# tviibh16m register map
Vendor: Infineon Technologies; Series: TVIIBH16M; File version: 1.0
CPU: CM7 r0p1, little endian, MPU, FPU, double-precision FPU, I-cache, D-cache, VTOR, ITCM, DTCM, 3 interrupt priority bits, 16 interrupts
Registers are 32-bit, read-write, reset 0x0 unless marked. A register's access mark holds for its fields unless they carry their own. Offsets are from the block's base; [hi:lo] are bit positions.

## ETH0 (part 1 of 3) — Ethernet Interface
Base 0x40480000
Same registers: ETH1 0x40490000
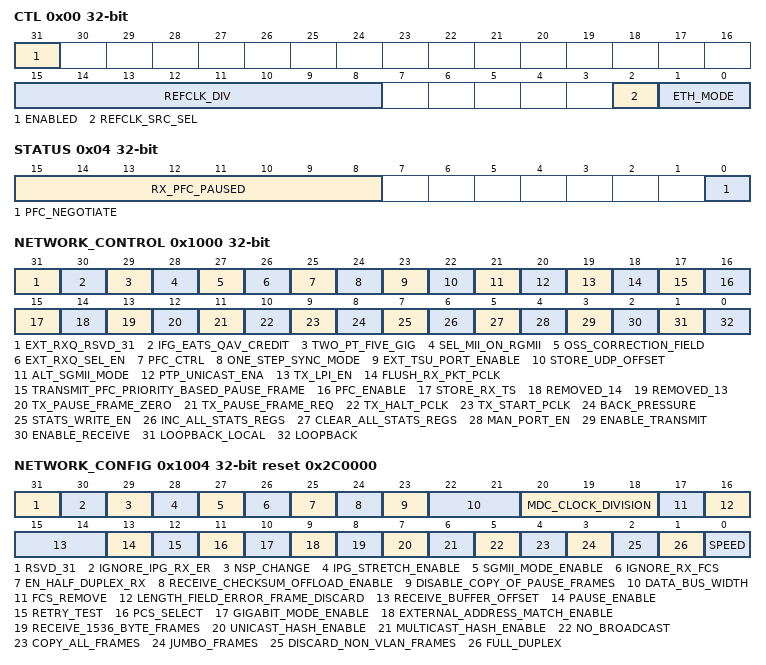
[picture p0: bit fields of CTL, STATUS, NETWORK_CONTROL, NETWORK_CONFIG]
0x00 CTL — MXETH Control Register
  [31] ENABLED — MXETH enable: '0': Disabled. '1': Enabled.
  [15:8] REFCLK_DIV — Specify the ref_clk divider. Integer division by (1+REFCLK_DIV). Allows for integer divisions in the range [1, 256].
  [2] REFCLK_SRC_SEL — Select the source for ref_clk. 0: Ref_clk comes from REF_CLK_IN input port (HSIO). 1: Ref_clk comes from REF_CLK_INT_IN input port (PLL).
  [1:0] ETH_MODE — Set ethernet mode. The speed of 10M/100M/1G is selected by programming network_config after IP is enabled. The field also specifies the clock source of internal tx_clk and rx_clk domain.
    0=MII (MII mode (10/100MHz speed is determined by network_config[0]).); 1=GMII (GMII mode (network_config[10] must be set to enable 1G operation).); 2=RGMII (RGMII mode (10M/100M/1G speed is determined by network_config[10] and network_config[0]).); 3=RMII (RMII mode (10M/100M speed is determined by network_config[0]).)
0x04 STATUS ro — MXETH Status Register
  [15:8] RX_PFC_PAUSED — Each bit corresponds to a priority indicated within the PFC priority based pause frame. Each bit is set when a PFC priority based pause frame has been received, and the associated priority pause time quantum is non-zero. Each bit is cleared when the associated pause time identified by the received pause time quantum has elapsed.
  [0] PFC_NEGOTIATE — Identifies that PFC priority based pause flow control has been negotiated. 0 - No PFC priority based pause frames have yet been received, flow control is being handled using classic 802.3 pause frames. 1 - At least one PFC priority based pause frames has been received. All subsequent 802.3 pause frames will be dropped.
0x1000 NETWORK_CONTROL — The network control register contains general MAC control functions for both receiver and transmitter.
  [31] EXT_RXQ_RSVD_31 ro
  [30] IFG_EATS_QAV_CREDIT — Setting this bit high modifies the CBS algorithm so the IFG/IPG associated with a transmit frame counts towards its 802.1Qav credit.
  [29] TWO_PT_FIVE_GIG — 2.5G operation selected - setting this bit high drives the speed_mode[3] top level output pin high and also adjusts the link timer in the PCS auto-negotiation block to ensure it delivers 10ms for 2500BASE-X and 1.6ms in SGMII mode, and also ensures int_moderation counts 800ns periods with the speeded up MAC clocks.
  [28] SEL_MII_ON_RGMII — If the RGMII interface being used set this bit high to configure the interface for MII operation.
  [27] OSS_CORRECTION_FIELD — 1588 One Step Correction Field Update. Set this bit high to enable updating the correction field of PTP 1588 version 2 sync frames by adding current TSU timer value.
  [26] EXT_RXQ_SEL_EN — Enable external selection of receive queue. When this bit is high the ext_match1, ext_match2, ext_match3 and ext_match4 inputs will determine which receive queue a frame is routed to. This will be the case regardless of the state of the external address match enable bit 9 of the network config register. Note that receive frames will be dropped unless they are matched by the internal frame filtering functionality. If the external address match enable bit 9 in the network config register is set frames may be matched by an external address match filter as long as one of the ext_match1, ext_match2, ext_match3 and ext_match4 inputs is asserted early enough. When set ext_rxq_sel_en takes precedence over the existing screener functionality. This bit is only relevant if priority queuing is configured.
  [25] PFC_CTRL — 'Enable multiple PFC pause quantums, one per pause priority'
  [24] ONE_STEP_SYNC_MODE — 1588 One Step Sync Mode. Write 1 to enable. Replace timestamp field in the 1588 header for TX Sync Frames with current TSU timer value.
  [23] EXT_TSU_PORT_ENABLE ro — Write ignore, read 0
  [22] STORE_UDP_OFFSET
  [21] ALT_SGMII_MODE — Alternative sgmii mode. If asserted with sgmii_mode in the network control register the ACK bit is driven before ability detect during transfer of status information from the PHY to the MAC.
  [20] PTP_UNICAST_ENA — Enable detection of unicast PTP unicast frames.
  [19] TX_LPI_EN — Enable LPI transmission when set LPI (low power idle) is immediately transmitted. LPI is transmitted even if bit 3 transmit enable is disabled. Setting this bit also sends a pause signal to the transmit datapath.
  [18] FLUSH_RX_PKT_PCLK wo — Flush the next packet from the external RX DPRAM. Writing one to this bit will only have an effect if the DMA is not currently writing a packet already stored in the DPRAM to memory. Self clearing register.
  [17] TRANSMIT_PFC_PRIORITY_BASED_PAUSE_FRAME wo — Write a one to transmit PFC priority based pause frame. Takes the values stored in the Transmit PFC Pause Register. Self clearing register.
  [16] PFC_ENABLE — Enable PFC Priority Based Pause Reception capabilities. Setting this bit will enable PFC negotiation and recognition of priority based pause frames.
  [15] STORE_RX_TS — Store receive time stamp to memory. Setting this bit to one will cause the CRC of every received frame to be replaced with the value of the nanoseconds field of the 1588 timer that was captured as the receive frame passed the message time stamp point. Set to zero for normal operation.
  [14] REMOVED_14 ro — Write ignore, read 0
  [13] REMOVED_13 ro — Write ignore, read 0
  [12] TX_PAUSE_FRAME_ZERO wo — Transmit zero quantum pause frame - writing one to this bit causes a pause frame with zero quantum to be transmitted.
  [11] TX_PAUSE_FRAME_REQ wo — Transmit pause frame - writing one to this bit causes a pause frame to be transmitted. Self clearing register.
  [10] TX_HALT_PCLK wo — Transmit halt - writing one to this bit halts transmission as soon as any ongoing frame transmission ends.
  [9] TX_START_PCLK wo — Start transmission - writing one to this bit starts transmission.
  [8] BACK_PRESSURE — Back pressure if set in 10M or 100M half duplex mode will force collisions on all received frames. Ignored in gigabit half duplex mode.
  [7] STATS_WRITE_EN — Write enable for statistics registers - setting this bit to one means the statistics registers can be written for functional test purposes.
  [6] INC_ALL_STATS_REGS wo — Incremental statistics registers - this bit is write only. Writing a one increments all the statistics registers by one for test purposes. Self clearing register.
  [5] CLEAR_ALL_STATS_REGS wo — Clear statistics registers - this bit is write only. Writing a one clears the statistics registers. Self clearing register.
  [4] MAN_PORT_EN — Management port enable - set to one to enable the management port. When zero forces mdio to high impedance state and mdc low.
  [3] ENABLE_TRANSMIT — Transmit enable - when set, it enables the GEM transmitter to send data. When reset transmission will stop immediately, the transmit pipeline and control registers will be cleared and the transmit queue pointer register will reset to point to the start of the transmit descriptor list.
  [2] ENABLE_RECEIVE — Receive enable - when set, it enables the GEM to receive data. When reset frame reception will stop immediately and the receive pipeline will be cleared. The receive queue pointer register is unaffected.
  [1] LOOPBACK_LOCAL — Loopback local - asserts the loopback_local signal to the system clock generator. Also connects txd to rxd, tx_en to rx_dv and forces full duplex mode. Bit 11 of the network configuration register must be set low to disable TBI mode when in internal loopback. rx_clk and tx_clk may malfunction as the GEM is switched into and out of internal loopback. It is important that receive and transmit circuits have already been disabled when making the switch into and out of internal loopback. Local loopback functionality is optional and may not be supported by some instantiations of the GEM.
  [0] LOOPBACK — Loopback - controls the loopback output pin.
0x1004 NETWORK_CONFIG reset 0x2C0000 — The network configuration register contains functions for setting the mode of operation for the Gigabit Ethernet MAC.
  [31] RSVD_31
  [30] IGNORE_IPG_RX_ER — Ignore IPG rx_er. When set rx_er has no effect on the GEMs operation when rx_dv is low. Set this when using the RGMII wrapper in half-duplex mode.
  [29] NSP_CHANGE — Receive bad preamble. When set frames with non-standard preamble are not rejected.
  [28] IPG_STRETCH_ENABLE — IPG stretch enable - when set the transmit IPG can be increased above 96 bit times depending on the previous frame length using the IPG stretch register.
  [27] SGMII_MODE_ENABLE — SGMII mode enable - changes behaviour of the auto-negotiation advertisement and link partner ability registers to meet the requirements of SGMII and reduces the duration of the link timer from 10 ms to 1.6 ms.
  [26] IGNORE_RX_FCS — Ignore RX FCS - when set frames with FCS/CRC errors will not be rejected. FCS error statistics will still be collected for frames with bad FCS and FCS status will be recorded in frame's DMA descriptor. For normal operation this bit must be set to zero.
  [25] EN_HALF_DUPLEX_RX — Enable frames to be received in half-duplex mode while transmitting. Must set '0', MXETH only supports full-duplex mode.
  [24] RECEIVE_CHECKSUM_OFFLOAD_ENABLE — Receive checksum offload enable - when set, the receive checksum engine is enabled. Frames with bad IP, TCP or UDP checksums are discarded.
  [23] DISABLE_COPY_OF_PAUSE_FRAMES — Disable copy of pause frames - set to one to prevent pause frames being copied to memory. When set, neither control frames with type id 8808, nor pause frames with destination address 010000c28001 are copied to memory, this functionality was enhanced in release 1p09 (mxeth uses 1p09). Note that valid pause frames received will still increment pause statistics and pause the transmission of frames as required.
  [22:21] DATA_BUS_WIDTH — Data bus width - set according to AMBA (AXI/AHB) or external FIFO data bus width. The reset value for this can be changed by defining a new value for gem_dma_bus_width_def in gem_defs. Only valid bus widths may be written if the system is configured to a maximum width less than 128-bits. 00: 32 bit data bus width 01: 64 bit AMBA (AXI/AHB) data bus width 10: 128 bit AMBA (AXI/AHB) data bus width 11: 128 bit AMBA (AXI/AHB) data bus width. Note. The reset value of this field is equal to the gem_dma_bus_width_def define, which is user configurable. Note: For AXI_MASTER_PRESENT=1, MXETH only supports 64b DMA data bus width, so must set it 1. For AXI_MASTER_PRESENT=0, MXETH only supports 32b DMA data bus width, so must set it 0.
  [20:18] MDC_CLOCK_DIVISION — MDC clock division - set according to pclk speed. These three bits determine the number pclk will be divided by to generate MDC. For conformance with the 802.3 specification, MDC must not exceed 2.5 MHz (MDC is only active during MDIO read and write operations). The reset value for this can be changed by defining a new value for gem_mdc_clock_div in gem_defs.v 000: divide pclk by 8 (pclk up to 20 MHz) 001: divide pclk by 16 (pclk up to 40 MHz) 010: divide pclk by 32 (pclk up to 80 MHz) 011: divide pclk by 48 (pclk up to 120MHz) 100: divide pclk by 64 (pclk up to 160 MHz) 101: divide pclk by 96 (pclk up to 240 MHz) 110: divide pclk by 128 (pclk up to 320 MHz) 111: divide pclk by 224 (pclk up to 540 MHz). Note. The reset value of this field is equal to the gem_mdc_clock_div define, which is user configurable.
  [17] FCS_REMOVE — FCS remove - setting this bit will cause received frames to be written to memory without their frame check sequence (last 4 bytes). The frame length indicated will be reduced by four bytes in this mode.
  [16] LENGTH_FIELD_ERROR_FRAME_DISCARD — Length field error frame discard - setting this bit causes frames with a measured length shorter than the extracted length field (as indicated by bytes 13 and 14 in a non-VLAN tagged frame) to be discarded. This only applies to frames with a length field less than 0x0600.
  [15:14] RECEIVE_BUFFER_OFFSET — Receive buffer offset - indicates the number of bytes by which the received data is offset from the start of the receive buffer.
  [13] PAUSE_ENABLE — Pause enable - when set, transmission will pause if a non zero 802.3 classic pause frame is received and PFC has not been negotiated.
  [12] RETRY_TEST — Retry test - must be set to zero for normal operation. If set to one the backoff between collisions will always be one slot time. Setting this bit to one helps test the too many retries condition. Also used in the pause frame tests to reduce the pause counter's decrement time from 512 bit times, to every rx_clk cycle.
  [11] PCS_SELECT — PCS select - selects between MII/GMII and TBI
  [10] GIGABIT_MODE_ENABLE — Gigabit mode enable - setting this bit configures the GEM for 1000 Mbps operation. 0: 10/100 operation using MII interface 1: Gigabit operation using GMI interface
  [9] EXTERNAL_ADDRESS_MATCH_ENABLE — External address match enable - when set the external address match interface can be used to copy frames to memory.
  [8] RECEIVE_1536_BYTE_FRAMES — Receive 1536 byte frames - setting this bit means the GEM will accept frames up to 1536 bytes in length. Normally the GEM would reject any frame above 1518 bytes.
  [7] UNICAST_HASH_ENABLE — Unicast hash enable - when set, unicast frames will be accepted when the 6 bit hash function of the destination address points to a bit that is set in the hash register.
  [6] MULTICAST_HASH_ENABLE — Multicast hash enable - when set, multicast frames will be accepted when the 6 bit hash function of the destination address points to a bit that is set in the hash register.
  [5] NO_BROADCAST — No broadcast - when set to logic one, frames addressed to the broadcast address of all ones will not be accepted.
  [4] COPY_ALL_FRAMES — Copy all frames - when set to logic one, all valid frames will be accepted.
  [3] JUMBO_FRAMES — Jumbo frames - set to one to enable jumbo frames up to `gem_jumbo_max_length bytes to be accepted. The default length is 10,240 bytes.
  [2] DISCARD_NON_VLAN_FRAMES — Discard non-VLAN frames - when set only VLAN tagged frames will be passed to the address matching logic.
  [1] FULL_DUPLEX — Full duplex - if set to logic one, the transmit block ignores the state of collision and carrier sense and allows receive while transmitting. Also controls the half_duplex pin.
  [0] SPEED — Speed - set to logic one to indicate 100Mbps operation, logic zero for 10Mbps.
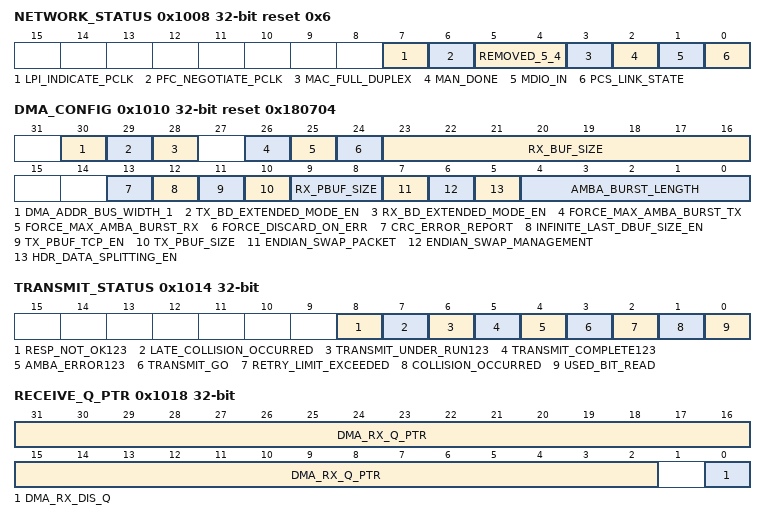
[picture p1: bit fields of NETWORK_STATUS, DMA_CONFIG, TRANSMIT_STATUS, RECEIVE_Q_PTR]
0x1008 NETWORK_STATUS ro reset 0x6 — The network status register returns status information with respect to the PHY management interface.
  [7] LPI_INDICATE_PCLK — LPI Indication - Low power idle has been detected on receive. This bit is set when LPI is detected and reset when normal idle is detected. An interrupt is generated when the state of this bit changes.
  [6] PFC_NEGOTIATE_PCLK — Set when PFC Priority Based Pause has been negotiated.
  [5:4] REMOVED_5_4
  [3] MAC_FULL_DUPLEX — PCS auto-negotiation duplex resolution. Set to one if the resolution function determines that both devices are capable of full duplex operation. If zero half-duplex operation is possible as long as bit 0 (PCS link state) is also one.
  [2] MAN_DONE — The PHY management logic is idle (i.e. has completed).
  [1] MDIO_IN — Returns status of the mdio_in pin.
  [0] PCS_LINK_STATE — Returns status of PCS link state. If auto-negotiation is disabled this returns the synchronisation status. If auto-negotiation is enabled it is set in the LINK_OK state as long as a compatible duplex mode is resolved.
0x100C USER_IO_REGISTER ro — Not presents. Access to the register will return AHB error.
  [31:0] RSVD_31_0 — Write ignore, read 0
0x1010 DMA_CONFIG reset 0x180704 — DMA Configuration Register
  [30] DMA_ADDR_BUS_WIDTH_1 — DMA address bus width. 0 = 32b, 1 = 64b. MXETH only supports 32b DMA address bus width, so must set it 0.
  [29] TX_BD_EXTENDED_MODE_EN — Enable TX extended BD mode. See TX BD control register definition for description of feature.
  [28] RX_BD_EXTENDED_MODE_EN — Enable RX extended BD mode. See RX BD control register definition for description of feature.
  [26] FORCE_MAX_AMBA_BURST_TX — Force max length bursts on TX. Force the TX DMA to always issue max length bursts on EOP(end of packet) or EOB(end of buffer) transfers as defined by bits 4:0 of this register, even when there is less that max burst data bytes to read. Residual data read is ignored. Does not apply on bursts that break 1k boundary rule.
  [25] FORCE_MAX_AMBA_BURST_RX — Force max length bursts on RX. Force the RX DMA to always issue max length bursts on EOP(end of packet) or EOB(end of buffer)transfers, even if there is less than max burst real packet data required to write. Any extra bytes of pad data is set to 0x00. Does not apply on bursts that break 1k boundary rule.
  [24] FORCE_DISCARD_ON_ERR — Auto Discard RX pkts during lack of resource. When set, the GEM DMA will automatically discard receive packets from the receiver packet buffer memory when no AMBA (AXI/AHB) resource is available. When low, then received packets will remain to be stored in the SRAM based packet buffer until AMBA (AXI/AHB) buffer resource next becomes available. A write to this bit is ignored if the DMA is not configured in the packet buffer full store and forward mode.
  [23:16] RX_BUF_SIZE — DMA receive buffer size in external AMBA (AXI/AHB) system memory. The value defined by these bits determines the size of buffer to use in main system memory when writing received data. The value is defined in multiples of 64 bytes. 0x01 corresponds to buffers of 64 bytes 0x02 corresponds to 128 bytes etc. For example: 0x02: 128 byte. 0x18: 1536 byte (1*max length frame/buffer) 0xA0: 10240 byte (1*10K jumbo frame/buffer) Note that this value should never be written as zero. Note. The reset value of this field is equal to the gem_rx_buffer_length_def define, which is user configurable.
  [13] CRC_ERROR_REPORT — When the bit is set, bit 16 of the receive buffer descriptor will represent FCS/CRC error (only if frames with FCS are copied to memory as enabled by bit 26 in the network config register). When this bit is clear, bit 16 of the receive buffer descriptor will represent the Canonical format indicator (CFI) bit as extracted from the receive frame (if the receive buffer descriptor is pointing to the last data buffer of the receive frame and the received frame was VLAN tagged).
  [12] INFINITE_LAST_DBUF_SIZE_EN — Forces the DMA to consider the data buffer pointed to by last descriptor in the descriptor list to be of infinite size.
  [11] TX_PBUF_TCP_EN
  [10] TX_PBUF_SIZE
  [9:8] RX_PBUF_SIZE
  [7] ENDIAN_SWAP_PACKET — endian swap mode enable for packet data accesses. When set, selects swapped endianism for AMBA (AXI/AHB) transfers. When clear, selects little endian mode. Note, the default value of this bit equals to `gem_endian_swap_def, which is design time configuration.
  [6] ENDIAN_SWAP_MANAGEMENT — endian swap mode enable for management descriptor accesses. When set, selects swapped endianism for AMBA (AXI/AHB) transfers. When clear, selects little endian mode. Note, the default value of this bit equals to `gem_endian_swap_def, which is design time configuration.
  [5] HDR_DATA_SPLITTING_EN — Enable header data Splitting. When set, receive frames will be forwarded to main memory using a minimum of two DMA data buffers. The first X data buffers will contain the frame header, consisting of the Ethernet,VLAN,(IPv4 or IPv6),(TCP or UDP). X= (frame header size divided by rx_buf_size as defined in bits 23:16 of this register). The last Y data buffers will contain the frame payload. Y= (frame payload size divided by rx_buf_size). Note that for non VLAN/IP/TCP/UDP frames, the header will always be 14 bytes. When this feature is disabled, the frame is forwarded to main memory in blocks of rx_buf_size. Note: For AXI_MASTER_PRESENT=0 i.e. AHB master support, this feature cannot be set.
  [4:0] AMBA_BURST_LENGTH — Selects the burst length to use on the AMBA (AHB/AXI) when transferring frame data. Not used for DMA management operations and only used where space and data size allow and respecting AXI/AHB burst boundary rules. One-hot priority encoding enforced automatically on register writes as follows, where x represents don't care: 1xxxx: Attempt to use bursts of up to 16. 01xxx: Attempt to use bursts of up to 8. 001xx: Attempt to use bursts of up to 4. 0001x: Always use SINGLE bursts. 00001: Always use SINGLE bursts. 00000: Attempt to use bursts of up to 256. Note: MXETH only supports burst length up to 16.
0x1014 TRANSMIT_STATUS — This register, when read, provides details of the status of a transmit. Once read, individual bits may be cleared by writing 1 to them. It is not possible to set a bit to 1 by writing to the register.
  [8] RESP_NOT_OK123 write-1-clears — bresp/hresp not OK - set when the DMA block sees bresp/hresp not OK. Cleared by writing a one to this bit.
  [7] LATE_COLLISION_OCCURRED write-1-clears — Late collision occurred - only set if the condition occurs in gigabit mode, as retry is not attempted. Cleared by writing a one to this bit.
  [6] TRANSMIT_UNDER_RUN123 write-1-clears — Transmit under run - this bit is set if the transmitter was forced to terminate a frame that it had already began transmitting due to further data being unavailable. This bit is set if a transmitter status write back has not completed when another status write back is attempted. When using the DMA interface configured for packet buffer mode, this bit will never be set. Cleared by writing a 1.
  [5] TRANSMIT_COMPLETE123 write-1-clears — Transmit complete - set when a frame has been transmitted. Cleared by writing a one to this bit.
  [4] AMBA_ERROR123 write-1-clears — Transmit frame corruption due to AMBA (AXI/AHB) errors. Set if an error occurs whilst midway through reading transmit frame from external memory including RRESP or BRESP errors and buffers exhausted mid frame (if the buffers run out during transmission of a frame then transmission stops, FCS shall be bad and tx_er asserted). Also set in DMA packet buffer mode if single frame is too large for configured packet buffer memory size. Cleared by writing a one to this bit.
  [3] TRANSMIT_GO ro — Transmit go - if high transmit is active. When using the exposed FIFO interface, this bit represents bit 3 of the network control register. When using the DMA interface this bit represents the tx_go variable as specified in the transmit buffer description.
  [2] RETRY_LIMIT_EXCEEDED write-1-clears — Retry limit exceeded - cleared by writing a one to this bit.
  [1] COLLISION_OCCURRED write-1-clears — Collision occurred - set by the assertion of collision. Cleared by writing a one to this bit. When operating in 10/100 mode, this status indicates either a collision or a late collision. In gigabit mode, this status is not set for a late collision.
  [0] USED_BIT_READ write-1-clears — Used bit read - set when a transmit buffer descriptor is read with its used bit set. Cleared by writing a one to this bit.
0x1018 RECEIVE_Q_PTR — This register holds the start address of the receive buffer queue (receive buffers descriptor list). The receive buffer queue base address must be initialized before receive is enabled through bit 2 of the network control register. Once reception is enabled, any write to the receive buffer queue base address register is ignored. Reading this register returns the location of the descriptor currently being accessed. This value increments as buffers are used. Software should not use this register for determining where to remove received frames from the queue as it constantly changes as new frames are received. Software should instead work its way through the buffer descriptor queue checking the used bits. In terms of AMBA (AXI) operation, the receive descriptors are read from memory using a single 32bit AXI access. When the datapath is configured at 64bit, the receive descriptors should be aligned at 64-bit boundaries and each pair of 32-bit descriptors is written to using a single 64bit AXI access.
  [31:2] DMA_RX_Q_PTR — Receive buffer queue base address - written with the address of the start of the receive queue.
  [0] DMA_RX_DIS_Q — Disable queue if set to 1. This can be used to reduce the number of active queues and should only be changed while receive is not enabled.
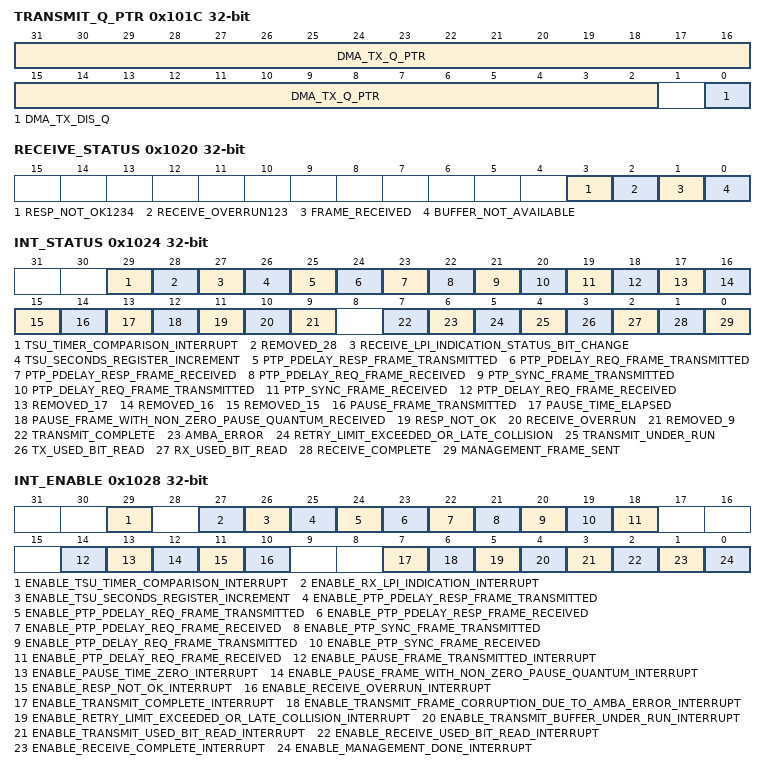
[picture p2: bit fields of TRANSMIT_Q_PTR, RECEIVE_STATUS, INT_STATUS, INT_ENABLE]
0x101C TRANSMIT_Q_PTR — This register holds the start address of the transmit buffer queue (transmit buffers descriptor list). The transmit buffer queue base address register must be initialized before transmit is started through bit 9 of the network control register. Once transmission has started, any write to the transmit buffer queue base address register is illegal and therefore ignored. Note that due to clock boundary synchronization, it takes a maximum of four pclk cycles from the writing of the transmit start bit before the transmitter is active. Writing to the transmit buffer queue base address register during this time may produce unpredictable results. Reading this register returns the location of the descriptor currently being accessed. Because the DMA can store data for multiple frames at once, this may not necessarily be pointing to the current frame being transmitted. In terms of AMBA AXI operation, the transmit descriptors are written to memory using a single 32bit AHB access. When the datapath is configured as 64bit, the transmit descriptors should be aligned at 64-bit boundaries and each pair of 32-bit descriptors is read from memory using a single AXI access.
  [31:2] DMA_TX_Q_PTR — Transmit buffer queue base address - written with the address of the start of the transmit queue.
  [0] DMA_TX_DIS_Q — Disable queue if set to 1. This can be used to reduce the number of active queues and should only be changed while transmit is not enabled.
0x1020 RECEIVE_STATUS — This register, when read provides details of the status of a receive. Once read, individual bits may be cleared by writing 1 to them. It is not possible to set a bit to 1 by writing to the register.
  [3] RESP_NOT_OK1234 write-1-clears — bresp not OK - set when the DMA block sees bresp/hresp not OK. Cleared by writing a one to this bit.
  [2] RECEIVE_OVERRUN123 write-1-clears — Receive overrun - this bit is set if either the gem_dma RX FIFO or external RX FIFO were unable to store the receive frame due to a FIFO overflow, or if the receive status, reported by the gem_rx module to the gem_dma was not taken at end of frame. This bit is also set in DMA packet buffer mode if the packet buffer overflows. For DMA operation the buffer will be recovered if an overrun occurs. This bit is cleared by writing a one to it.
  [1] FRAME_RECEIVED write-1-clears — Frame received - one or more frames have been received and placed in memory. Cleared by writing a one to this bit.
  [0] BUFFER_NOT_AVAILABLE write-1-clears — Buffer not available - an attempt was made to get a new buffer and the pointer indicated that it was owned by the processor. The DMA will reread the pointer each time an end of frame is received until a valid pointer is found. This bit is set following each descriptor read attempt that fails, even if consecutive pointers are unsuccessful and software has in the mean time cleared the status flag. Cleared by writing a one to this bit.
0x1024 INT_STATUS — If not configured for priority queueing, the GEM generates a single interrupt. This register indicates the source of this interrupt. The corresponding bit in the mask register must be clear for a bit to be set. If any bit is set in this register the ethernet_int signal will be asserted. For test purposes each bit can be set or reset by writing to the interrupt mask register. The default configuration is shown below whereby all bits are reset to zero on read. Changing the validity of the `gem_irq_read_clear define will instead require a one to be written to the appropriate bit in order to clear it. In this mode reading has no affect on the status of the bit.
  [29] TSU_TIMER_COMPARISON_INTERRUPT wo write-1-clears — TSU timer comparison interrupt. Indicates when TSU timer count value is equal to programmed value.
  [28] REMOVED_28 ro — Write ignore, read 0
  [27] RECEIVE_LPI_INDICATION_STATUS_BIT_CHANGE wo write-1-clears
  [26] TSU_SECONDS_REGISTER_INCREMENT wo write-1-clears — TSU seconds register increment indicates the register has incremented. Cleared on read.
  [25] PTP_PDELAY_RESP_FRAME_TRANSMITTED wo write-1-clears — PTP pdelay_resp frame transmitted indicates a PTP pdelay_resp frame has been transmitted. Cleared on read.
  [24] PTP_PDELAY_REQ_FRAME_TRANSMITTED wo write-1-clears — PTP pdelay_req frame transmitted indicates a PTP pdelay_req frame has been transmitted. Cleared on read.
  [23] PTP_PDELAY_RESP_FRAME_RECEIVED wo write-1-clears — PTP pdelay_resp frame received indicates a PTP pdelay_resp frame has been received. Cleared on read.
  [22] PTP_PDELAY_REQ_FRAME_RECEIVED wo write-1-clears — PTP pdelay_req frame received indicates a PTP pdelay_req frame has been received. Cleared on read.
  [21] PTP_SYNC_FRAME_TRANSMITTED wo write-1-clears — PTP sync frame transmitted indicates a PTP sync frame has been transmitted. Cleared on read.
  [20] PTP_DELAY_REQ_FRAME_TRANSMITTED wo write-1-clears — PTP delay_req frame transmitted indicates a PTP delay_req frame has been transmitted. Cleared on read.
  [19] PTP_SYNC_FRAME_RECEIVED wo write-1-clears — PTP sync frame received indicates a PTP sync frame has been received. Cleared on read.
  [18] PTP_DELAY_REQ_FRAME_RECEIVED wo write-1-clears — PTP delay_req frame received indicates a PTP delay_req frame has been received. Cleared on read.
  [17] REMOVED_17 ro — Write ignore, read 0
  [16] REMOVED_16 ro — Write ignore, read 0
  [15] REMOVED_15 ro — Write ignore, read 0
  [14] PAUSE_FRAME_TRANSMITTED wo write-1-clears — Pause frame transmitted - indicates a pause frame has been successfully transmitted after being initiated from the network control register or from the tx_pause control pin. Cleared on read.
  [13] PAUSE_TIME_ELAPSED wo write-1-clears — Pause Time elapsed. set when either the pause time register at address 0x38 decrements to zero, or when a valid pause frame is received with a zero pause quantum field. Cleared on read.
  [12] PAUSE_FRAME_WITH_NON_ZERO_PAUSE_QUANTUM_RECEIVED wo write-1-clears — Pause frame with non-zero pause quantum received - indicates a valid pause has been received that has a non-zero pause quantum field. Cleared on read.
  [11] RESP_NOT_OK wo write-1-clears — bresp not OK - set when the DMA block sees bresp not OK. Cleared on read.
  [10] RECEIVE_OVERRUN wo write-1-clears — Receive overrun - set when the receive overrun status bit gets set. Cleared on read.
  [9] REMOVED_9 ro — Write ignore, read 0
  [7] TRANSMIT_COMPLETE wo write-1-clears — Transmit complete - set when a frame has been transmitted. Cleared on read.
  [6] AMBA_ERROR write-1-clears — Transmit frame corruption due to AMBA (AXI/AHB) error. Set if an error occurs whilst midway through reading transmit frame from external system memory, including HRESP (AHB), RRESP or BRESP(AXI) errors and buffers exhausted mid frame (if the buffers run out during transmission of a frame then transmission stops, FCS shall be bad and tx_er asserted). Also set in DMA packet buffer mode if single frame is too large for configured packet buffer memory size. Cleared on a read.
  [5] RETRY_LIMIT_EXCEEDED_OR_LATE_COLLISION write-1-clears — Retry limit exceeded or late collision - transmit error. Late collision will only cause this status bit to be set in gigabit mode (as a retry is not attempted). Cleared on read.
  [4] TRANSMIT_UNDER_RUN write-1-clears — Transmit under run - this interrupt is set if the transmitter was forced to terminate a frame that it has already began transmitting due to further data being unavailable. If an under run occurs, the transmitter will force bad crc and tx_er high. This interrupt is set if a transmitter status write back has not completed when another status write back is attempted. When using the DMA interface configured for internal FIFO mode, this interrupt is also set when the transmit DMA has written the SOP data into the FIFO and either the AHB bus was not granted in time for further data, or because an AHB/AXI error response was returned by the connected slave, or because a used bit was read. When using the DMA interface configured for packet buffer mode, this bit will never be set. When using the external FIFO interface, this interrupt is also set when the tx_r_underflow input was asserted during a frame transfer. Cleared on read.
  [3] TX_USED_BIT_READ write-1-clears — TX used bit read - set when a transmit buffer descriptor is read with its used bit set. Cleared on read.
  [2] RX_USED_BIT_READ write-1-clears — RX used bit read - set when a receive buffer descriptor is read with its used bit set. Cleared on read.
  [1] RECEIVE_COMPLETE write-1-clears — Receive complete - a frame has been stored in memory. Cleared on read.
  [0] MANAGEMENT_FRAME_SENT write-1-clears — Management frame sent - the PHY maintenance register has completed its operation. Cleared on read.
0x1028 INT_ENABLE wo — At reset all interrupts are disabled. Writing a one to the relevant bit location enables the required interrupt. This register is write only and when read will return zero.
  [29] ENABLE_TSU_TIMER_COMPARISON_INTERRUPT
  [27] ENABLE_RX_LPI_INDICATION_INTERRUPT
  [26] ENABLE_TSU_SECONDS_REGISTER_INCREMENT
  [25] ENABLE_PTP_PDELAY_RESP_FRAME_TRANSMITTED
  [24] ENABLE_PTP_PDELAY_REQ_FRAME_TRANSMITTED
  [23] ENABLE_PTP_PDELAY_RESP_FRAME_RECEIVED
  [22] ENABLE_PTP_PDELAY_REQ_FRAME_RECEIVED
  [21] ENABLE_PTP_SYNC_FRAME_TRANSMITTED
  [20] ENABLE_PTP_DELAY_REQ_FRAME_TRANSMITTED
  [19] ENABLE_PTP_SYNC_FRAME_RECEIVED
  [18] ENABLE_PTP_DELAY_REQ_FRAME_RECEIVED
  [14] ENABLE_PAUSE_FRAME_TRANSMITTED_INTERRUPT
  [13] ENABLE_PAUSE_TIME_ZERO_INTERRUPT
  [12] ENABLE_PAUSE_FRAME_WITH_NON_ZERO_PAUSE_QUANTUM_INTERRUPT
  [11] ENABLE_RESP_NOT_OK_INTERRUPT — Enable bresp not OK interrupt
  [10] ENABLE_RECEIVE_OVERRUN_INTERRUPT
  [7] ENABLE_TRANSMIT_COMPLETE_INTERRUPT
  [6] ENABLE_TRANSMIT_FRAME_CORRUPTION_DUE_TO_AMBA_ERROR_INTERRUPT — Enable transmit frame corruption due to AMBA (AXI/AHB) error interrupt
  [5] ENABLE_RETRY_LIMIT_EXCEEDED_OR_LATE_COLLISION_INTERRUPT
  [4] ENABLE_TRANSMIT_BUFFER_UNDER_RUN_INTERRUPT
  [3] ENABLE_TRANSMIT_USED_BIT_READ_INTERRUPT
  [2] ENABLE_RECEIVE_USED_BIT_READ_INTERRUPT
  [1] ENABLE_RECEIVE_COMPLETE_INTERRUPT
  [0] ENABLE_MANAGEMENT_DONE_INTERRUPT
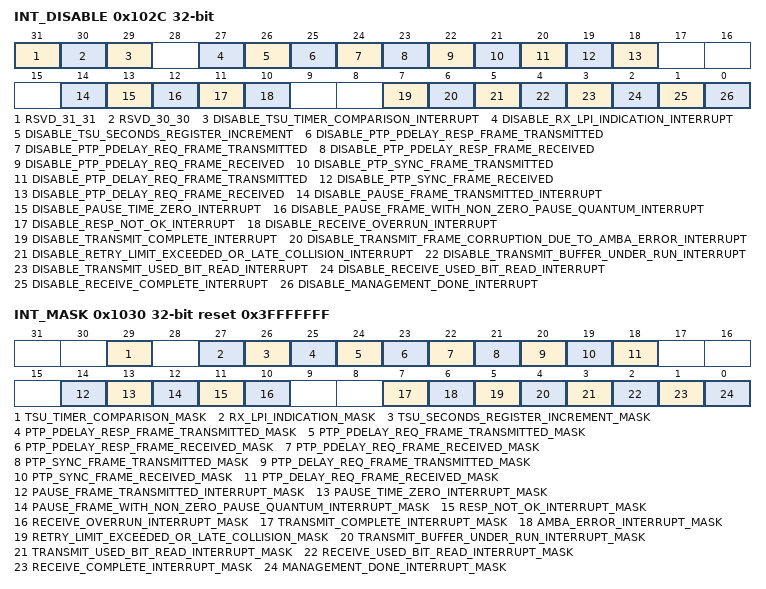
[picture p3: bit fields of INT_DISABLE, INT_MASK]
0x102C INT_DISABLE — Writing a 1 to the relevant bit location disables that particular interrupt. This register is write only and when read will return zero.
  [31] RSVD_31_31 ro
  [30] RSVD_30_30 ro
  [29] DISABLE_TSU_TIMER_COMPARISON_INTERRUPT wo
  [27] DISABLE_RX_LPI_INDICATION_INTERRUPT wo
  [26] DISABLE_TSU_SECONDS_REGISTER_INCREMENT wo
  [25] DISABLE_PTP_PDELAY_RESP_FRAME_TRANSMITTED wo
  [24] DISABLE_PTP_PDELAY_REQ_FRAME_TRANSMITTED wo
  [23] DISABLE_PTP_PDELAY_RESP_FRAME_RECEIVED wo
  [22] DISABLE_PTP_PDELAY_REQ_FRAME_RECEIVED wo
  [21] DISABLE_PTP_SYNC_FRAME_TRANSMITTED wo
  [20] DISABLE_PTP_DELAY_REQ_FRAME_TRANSMITTED wo
  [19] DISABLE_PTP_SYNC_FRAME_RECEIVED wo
  [18] DISABLE_PTP_DELAY_REQ_FRAME_RECEIVED wo
  [14] DISABLE_PAUSE_FRAME_TRANSMITTED_INTERRUPT wo
  [13] DISABLE_PAUSE_TIME_ZERO_INTERRUPT wo
  [12] DISABLE_PAUSE_FRAME_WITH_NON_ZERO_PAUSE_QUANTUM_INTERRUPT wo
  [11] DISABLE_RESP_NOT_OK_INTERRUPT wo — 'Disable bresp/hresp not OK interrupt'
  [10] DISABLE_RECEIVE_OVERRUN_INTERRUPT wo
  [7] DISABLE_TRANSMIT_COMPLETE_INTERRUPT wo
  [6] DISABLE_TRANSMIT_FRAME_CORRUPTION_DUE_TO_AMBA_ERROR_INTERRUPT wo — 'Disable transmit frame corruption due to AMBA (AHB/AXI) error interrupt'
  [5] DISABLE_RETRY_LIMIT_EXCEEDED_OR_LATE_COLLISION_INTERRUPT wo
  [4] DISABLE_TRANSMIT_BUFFER_UNDER_RUN_INTERRUPT wo
  [3] DISABLE_TRANSMIT_USED_BIT_READ_INTERRUPT wo
  [2] DISABLE_RECEIVE_USED_BIT_READ_INTERRUPT wo
  [1] DISABLE_RECEIVE_COMPLETE_INTERRUPT wo
  [0] DISABLE_MANAGEMENT_DONE_INTERRUPT wo
0x1030 INT_MASK ro reset 0x3FFFFFFF — The interrupt mask register is a read only register indicating which interrupts are masked. All bits are set at reset and can be reset individually by writing to the interrupt enable register or set individually by writing to the interrupt disable register. Having separate address locations for enable and disable saves the need for performing a read modify write when updating the interrupt mask register. For test purposes there is a write-only function to this register that allows the bits in the interrupt status register to be set or cleared, regardless of the state of the mask register.
  [29] TSU_TIMER_COMPARISON_MASK — Enable TSU timer comparison interrupt mask.
  [27] RX_LPI_INDICATION_MASK — A read of this register returns the value of the RX LPI indication mask. 0: Interrupt is enabled. 1: Interrupt is disabled. A write to this register directly affects the state of the corresponding bit in the interrupt status register, causing an interrupt to be generated if a 1 is written
  [26] TSU_SECONDS_REGISTER_INCREMENT_MASK — A read of this register returns the value of the TSU seconds register increment mask. 0: Interrupt is enabled. 1: Interrupt is disabled. A write to this register directly affects the state of the corresponding bit in the interrupt status register, causing an interrupt to be generated if a 1 is written.
  [25] PTP_PDELAY_RESP_FRAME_TRANSMITTED_MASK — A read of this register returns the value of the PTP pdelay_resp frame transmitted mask. 0: Interrupt is enabled. 1: Interrupt is disabled. A write to this register directly affects the state of the corresponding bit in the interrupt status register, causing an interrupt to be generated if a 1 is written.
  [24] PTP_PDELAY_REQ_FRAME_TRANSMITTED_MASK — A read of this register returns the value of the PTP pdelay_req frame transmitted mask. 0: Interrupt is enabled. 1: Interrupt is disabled. A write to this register directly affects the state of the corresponding bit in the interrupt status register, causing an interrupt to be generated if a 1 is written.
  [23] PTP_PDELAY_RESP_FRAME_RECEIVED_MASK — A read of this register returns the value of the PTP pdelay_resp frame received mask. 0: Interrupt is enabled. 1: Interrupt is disabled. A write to this register directly affects the state of the corresponding bit in the interrupt status register, causing an interrupt to be generated if a 1 is written.
  [22] PTP_PDELAY_REQ_FRAME_RECEIVED_MASK — A read of this register returns the value of the PTP pdelay_req frame received mask. 0: Interrupt is enabled. 1: Interrupt is disabled. A write to this register directly affects the state of the corresponding bit in the interrupt status register, causing an interrupt to be generated if a 1 is written.
  [21] PTP_SYNC_FRAME_TRANSMITTED_MASK — A read of this register returns the value of the PTP sync frame transmitted mask. 0: Interrupt is enabled. 1: Interrupt is disabled. A write to this register directly affects the state of the corresponding bit in the interrupt status register, causing an interrupt to be generated if a 1 is written.
  [20] PTP_DELAY_REQ_FRAME_TRANSMITTED_MASK — A read of this register returns the value of the PTP delay_req frame transmitted mask. 0: Interrupt is enabled. 1: Interrupt is disabled. A write to this register directly affects the state of the corresponding bit in the interrupt status register, causing an interrupt to be generated if a 1 is written.
  [19] PTP_SYNC_FRAME_RECEIVED_MASK — A read of this register returns the value of the PTP sync frame received mask. 0: Interrupt is enabled. 1: Interrupt is disabled. A write to this register directly affects the state of the corresponding bit in the interrupt status register, causing an interrupt to be generated if a 1 is written.
  [18] PTP_DELAY_REQ_FRAME_RECEIVED_MASK — A read of this register returns the value of the PTP delay_req frame received mask. 0: Interrupt is enabled. 1: Interrupt is disabled. A write to this register directly affects the state of the corresponding bit in the interrupt status register, causing an interrupt to be generated if a 1 is written.
  [14] PAUSE_FRAME_TRANSMITTED_INTERRUPT_MASK — pause frame transmitted interrupt mask. 0: Interrupt is enabled. 1: Interrupt is disabled. A write to this register directly affects the state of the corresponding bit in the interrupt status register, causing an interrupt to be generated if a 1 is written.
  [13] PAUSE_TIME_ZERO_INTERRUPT_MASK — pause time zero interrupt mask. 0: Interrupt is enabled. 1: Interrupt is disabled. A write to this register directly affects the state of the corresponding bit in the interrupt status register, causing an interrupt to be generated if a 1 is written.
  [12] PAUSE_FRAME_WITH_NON_ZERO_PAUSE_QUANTUM_INTERRUPT_MASK — pause frame with non-zero pause quantum interrupt mask. 0: Interrupt is enabled. 1: Interrupt is disabled. A write to this register directly affects the state of the corresponding bit in the interrupt status register, causing an interrupt to be generated if a 1 is written.
  [11] RESP_NOT_OK_INTERRUPT_MASK — bresp not OK interrupt mask. 0: Interrupt is enabled. 1: Interrupt is disabled. A write to this register directly affects the state of the corresponding bit in the interrupt status register, causing an interrupt to be generated if a 1 is written.
  [10] RECEIVE_OVERRUN_INTERRUPT_MASK — receive overrun interrupt mask. 0: Interrupt is enabled. 1: Interrupt is disabled. A write to this register directly affects the state of the corresponding bit in the interrupt status register, causing an interrupt to be generated if a 1 is written.
  [7] TRANSMIT_COMPLETE_INTERRUPT_MASK — transmit complete interrupt mask. 0: Interrupt is enabled. 1: Interrupt is disabled. A write to this register directly affects the state of the corresponding bit in the interrupt status register, causing an interrupt to be generated if a 1 is written.
  [6] AMBA_ERROR_INTERRUPT_MASK — transmit frame corruption due to AMBA (AXI) error interrupt mask. 0: Interrupt is enabled. 1: Interrupt is disabled. A write to this register directly affects the state of the corresponding bit in the interrupt status register, causing an interrupt to be generated if a 1 is written.
  [5] RETRY_LIMIT_EXCEEDED_OR_LATE_COLLISION_MASK — A read of this register returns the value of the retry limit exceeded or late collision (gigabit mode only) interrupt mask. 0: Interrupt is enabled. 1: Interrupt is disabled. A write to this register directly affects the state of the corresponding bit in the interrupt status register, causing an interrupt to be generated if a 1 is written.
  [4] TRANSMIT_BUFFER_UNDER_RUN_INTERRUPT_MASK — transmit buffer under run interrupt mask. 0: Interrupt is enabled. 1: Interrupt is disabled. A write to this register directly affects the state of the corresponding bit in the interrupt status register, causing an interrupt to be generated if a 1 is written.
  [3] TRANSMIT_USED_BIT_READ_INTERRUPT_MASK — transmit used bit read interrupt mask. 0: Interrupt is enabled. 1: Interrupt is disabled. A write to this register directly affects the state of the corresponding bit in the interrupt status register, causing an interrupt to be generated if a 1 is written.
  [2] RECEIVE_USED_BIT_READ_INTERRUPT_MASK — receive used bit read interrupt mask. 0: Interrupt is enabled. 1: Interrupt is disabled. A write to this register directly affects the state of the corresponding bit in the interrupt status register, causing an interrupt to be generated if a 1 is written.
  [1] RECEIVE_COMPLETE_INTERRUPT_MASK — receive complete interrupt mask. 0: Interrupt is enabled. 1: Interrupt is disabled. A write to this register directly affects the state of the corresponding bit in the interrupt status register, causing an interrupt to be generated if a 1 is written.
  [0] MANAGEMENT_DONE_INTERRUPT_MASK — management done interrupt mask. 0: Interrupt is enabled. 1: Interrupt is disabled. A write to this register directly affects the state of the corresponding bit in the interrupt status register, causing an interrupt to be generated if a 1 is written.
